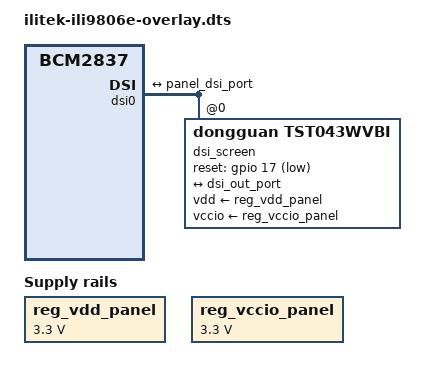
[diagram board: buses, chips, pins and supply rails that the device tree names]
/*
 * Device Tree Overlay for the ilitek-ili9806e DSI screen. This is designed to
 * work with the TST043WVBI-130C 4.3 inch DSI screen.
 */

/dts-v1/;
/plugin/;

/ {
	// use "brcmm,bcm2835" for RPi SoCs, use "brcm,bcm2837" for compute
	// modules, and use "brcm,bcm2711" for RPi 4
	compatible = "brcm,bcm2837";

	fragment@0 {
		target-path = "/";
		__overlay__ {
			reg_vdd_panel: tst043wvbi-regulator-vdd {
				compatible = "regulator-fixed";
				regulator-name = "tst043wvbi-vdd";
				regulator-min-microvolt = <3300000>;
				regulator-max-microvolt = <3300000>;
				regulator-always-on;
			};

			reg_vccio_panel: tst043wvbi-regulator-vccio {
				compatible = "regulator-fixed";
				regulator-name = "tst043wvbi-vccio";
				regulator-min-microvolt = <3300000>;
				regulator-max-microvolt = <3300000>;
				regulator-always-on;
			};
		};
	};

	fragment@1 {
		target = <&dsi0>;
		__overlay__ {
			status = "okay";
			#address-cells = <1>;
			#size-cells = <0>;
			port {
				dsi_out_port:endpoint {
					remote-endpoint = <&panel_dsi_port>;
				};
			};

			// ili9806e driver has two compatiblity strings:
			// 1. densitron,dmt028vghmcmi-1d
			// 2. ortustech,com35h3p70ulc
			dsi_screen:tst043wvbi@0 {
				compatible = "dongguan,tst043wvbi";
				status = "okay";
				reg = <0>;

				// RESET gpio, use 1 to set active low
				reset-gpios = <&gpio 17 1>;

				vdd-supply = <&reg_vdd_panel>;
				vccio-supply = <&reg_vccio_panel>;

				port {
					panel_dsi_port:endpoint {
						remote-endpoint = <&dsi_out_port>;
					};
				};
			};
		};
	};

	fragment@2 {
		target = <&gpio>;
		__overlay__ {
			dsi_screen_pins:tst043wvbi_pins {
				brcm,pins = <17>;
				brcm,function = <1>; // set gpio pin to output (1)
				brcm,pull = <0>; // unset pulldown of gpio pin (no pulldown or pullup)
			};
		};
	};

	__overrides__ {
		reset = <&dsi_screen_pins>,"brcm,pins:8",
			<&dsi_screen>,"reset-gpios:4";
	};
};
